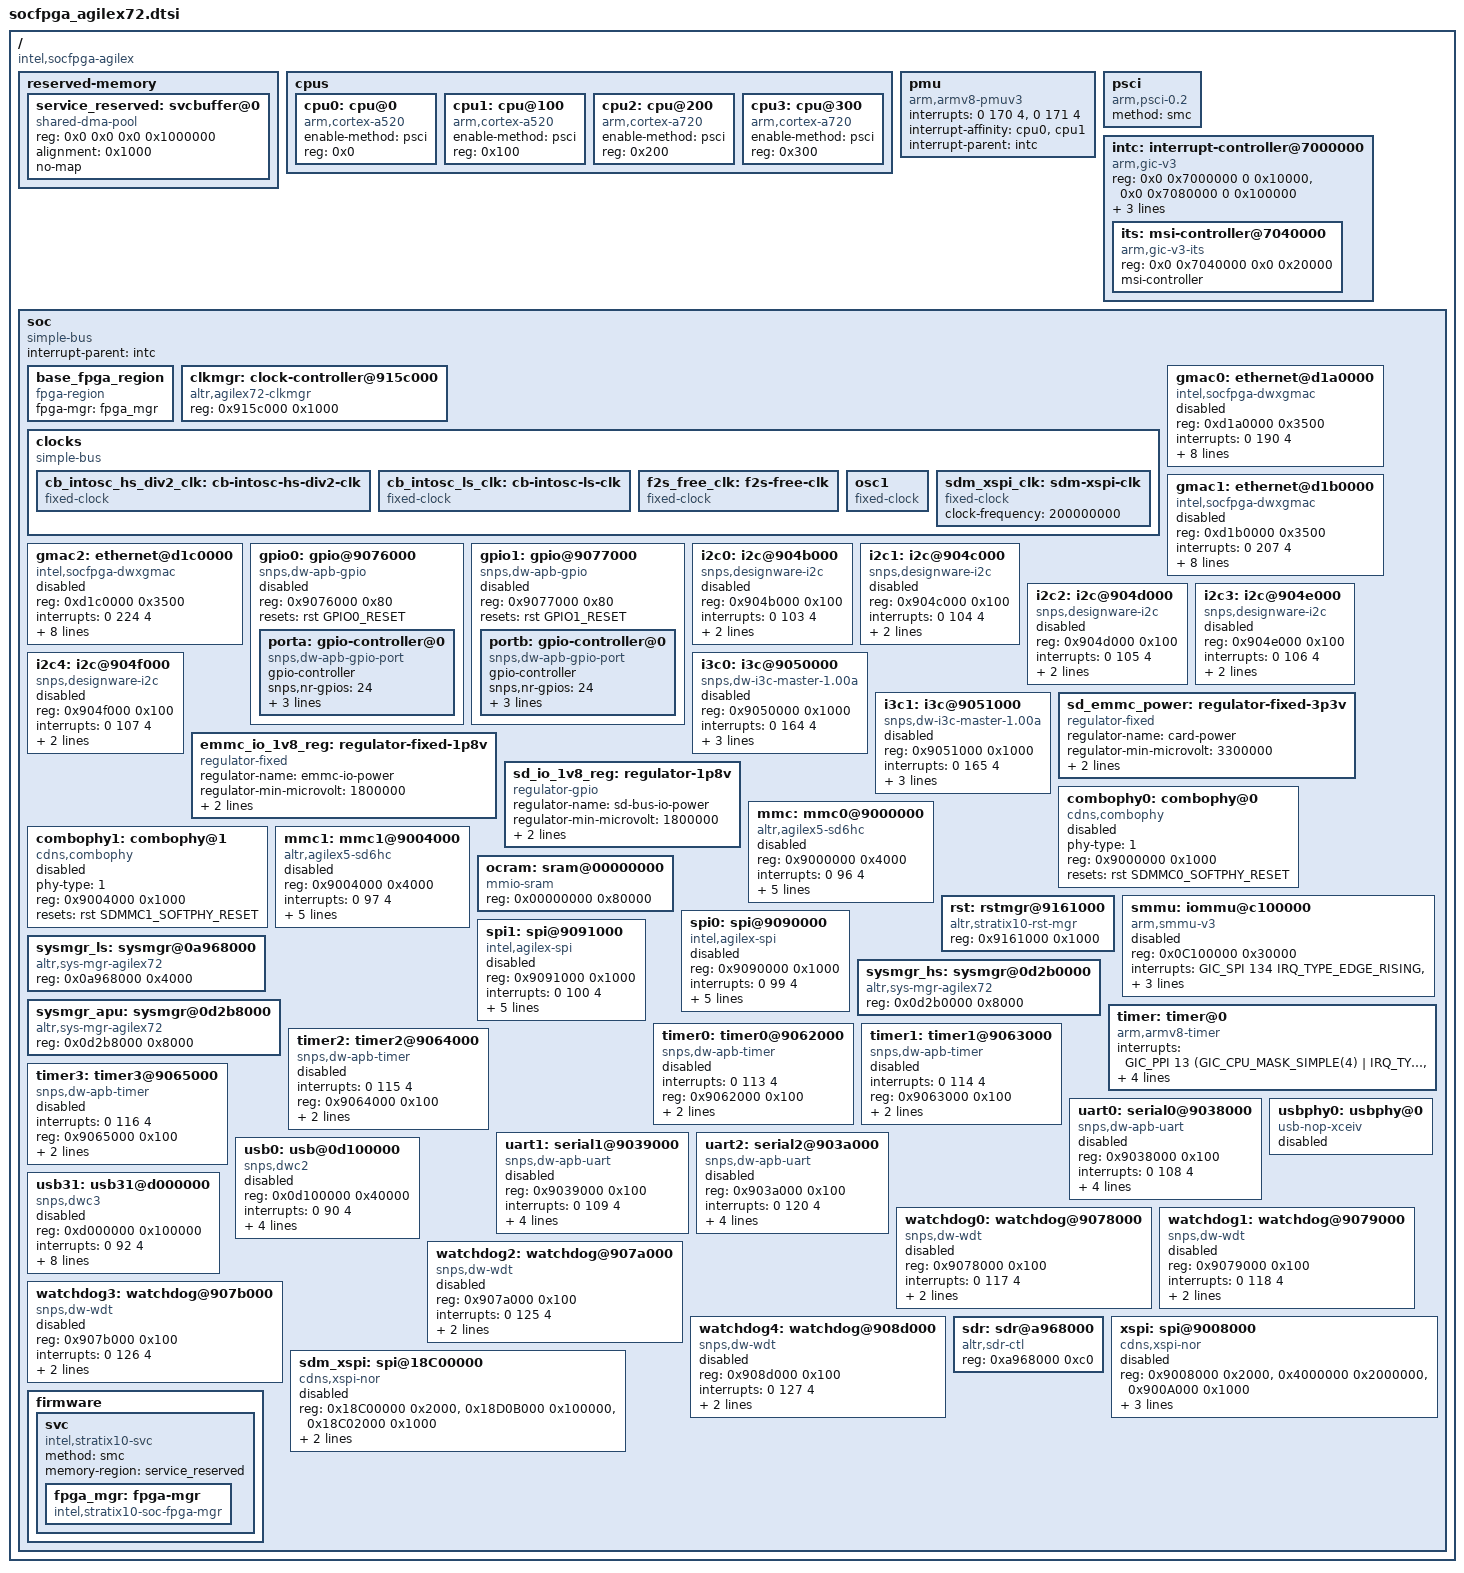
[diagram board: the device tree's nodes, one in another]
// SPDX-License-Identifier:     GPL-2.0
/*
 * Copyright (C) 2025-2026 Altera Corporation <www.altera.com>
 */

/dts-v1/;
#include <dt-bindings/reset/altr,rst-mgr-agilex72.h>
#include <dt-bindings/gpio/gpio.h>
#include <dt-bindings/clock/altr,agilex72-clkmgr.h>
#include <dt-bindings/interrupt-controller/arm-gic.h>
#include <dt-bindings/interrupt-controller/irq.h>

/ {
	compatible = "intel,socfpga-agilex";
	#address-cells = <2>;
	#size-cells = <2>;

	reserved-memory {
		#address-cells = <2>;
		#size-cells = <2>;
		ranges;

		service_reserved: svcbuffer@0 {
			compatible = "shared-dma-pool";
			reg = <0x0 0x0 0x0 0x1000000>;
			alignment = <0x1000>;
			no-map;
		};
	};

	cpus {
		#address-cells = <1>;
		#size-cells = <0>;

		cpu0: cpu@0 {
			compatible = "arm,cortex-a520";
			device_type = "cpu";
			enable-method = "psci";
			reg = <0x0>;
		};

		cpu1: cpu@100 {
			compatible = "arm,cortex-a520";
			device_type = "cpu";
			enable-method = "psci";
			reg = <0x100>;
		};

		cpu2: cpu@200 {
			compatible = "arm,cortex-a720";
			device_type = "cpu";
			enable-method = "psci";
			reg = <0x200>;
		};

		cpu3: cpu@300 {
			compatible = "arm,cortex-a720";
			device_type = "cpu";
			enable-method = "psci";
			reg = <0x300>;
		};
	};

	pmu {
		compatible = "arm,armv8-pmuv3";
		interrupts = <0 170 4>,
			     <0 171 4>;
		interrupt-affinity = <&cpu0>,
				     <&cpu1>;
		interrupt-parent = <&intc>;
	};

	psci {
		compatible = "arm,psci-0.2";
		method = "smc";
	};

	intc: interrupt-controller@7000000 {
		compatible = "arm,gic-v3";
		reg = <0x0 0x7000000 0 0x10000>,
			<0x0 0x7080000 0 0x100000>;
		ranges;
		#interrupt-cells = <3>;
		#address-cells = <2>;
		#size-cells = <2>;
		interrupt-controller;
		#redistributor-regions = <1>;
		redistributor-stride = <0x0 0x40000>;

		its: msi-controller@7040000 {
			compatible = "arm,gic-v3-its";
			reg = <0x0 0x7040000 0x0 0x20000>;
			msi-controller;
			#msi-cells = <1>;
		};
	};

	soc {
		#address-cells = <1>;
		#size-cells = <1>;
		compatible = "simple-bus";
		device_type = "soc";
		interrupt-parent = <&intc>;
		ranges = <0 0 0 0xffffffff>;

		base_fpga_region {
			#address-cells = <0x1>;
			#size-cells = <0x1>;
			compatible = "fpga-region";
			fpga-mgr = <&fpga_mgr>;
		};

		clkmgr: clock-controller@915c000 {
			compatible = "altr,agilex72-clkmgr";
			reg = <0x915c000 0x1000>;
			#clock-cells = <1>;
		};

		clocks {
			compatible = "simple-bus";

			cb_intosc_hs_div2_clk: cb-intosc-hs-div2-clk {
				#clock-cells = <0>;
				compatible = "fixed-clock";
			};

			cb_intosc_ls_clk: cb-intosc-ls-clk {
				#clock-cells = <0>;
				compatible = "fixed-clock";
			};

			f2s_free_clk: f2s-free-clk {
				#clock-cells = <0>;
				compatible = "fixed-clock";
			};

			osc1: osc1 {
				#clock-cells = <0>;
				compatible = "fixed-clock";
			};

			sdm_xspi_clk: sdm-xspi-clk {
				#clock-cells = <0>;
				compatible = "fixed-clock";
				clock-frequency = <200000000>;
			};
		};
		gmac0: ethernet@d1a0000 {
			compatible = "intel,socfpga-dwxgmac", "snps,dwxgmac-2.10", "snps,dwxgmac";
			reg = <0xd1a0000 0x3500>;
			interrupts = <0 190 4>;
			interrupt-names = "macirq";
			mac-address = [00 00 00 00 00 00];
			resets = <&rst EMAC0_RESET>;
			reset-names = "stmmaceth";
			tx-fifo-depth = <32768>;
			rx-fifo-depth = <16384>;
			iommus = <&smmu 1>;
			altr,sysmgr-syscon = <&sysmgr_hs 0x6C 0>;
			clocks = <&clkmgr AGILEX72_EMAC0_CLK>,
				 <&clkmgr AGILEX72_EMAC_PTP_CLK>;
			clock-names = "stmmaceth", "ptp_ref";
			status = "disabled";
		};

		gmac1: ethernet@d1b0000 {
			compatible = "intel,socfpga-dwxgmac", "snps,dwxgmac-2.10", "snps,dwxgmac";
			reg = <0xd1b0000 0x3500>;
			interrupts = <0 207 4>;
			interrupt-names = "macirq";
			mac-address = [00 00 00 00 00 00];
			resets = <&rst EMAC1_RESET>;
			reset-names = "stmmaceth";
			tx-fifo-depth = <32768>;
			rx-fifo-depth = <16384>;
			iommus = <&smmu 2>;
			altr,sysmgr-syscon = <&sysmgr_hs 0x74 0>;
			clocks = <&clkmgr AGILEX72_EMAC1_CLK>,
				 <&clkmgr AGILEX72_EMAC_PTP_CLK>;
			clock-names = "stmmaceth", "ptp_ref";
			status = "disabled";
		};

		gmac2: ethernet@d1c0000 {
			compatible = "intel,socfpga-dwxgmac", "snps,dwxgmac-2.10", "snps,dwxgmac";
			reg = <0xd1c0000 0x3500>;
			interrupts = <0 224 4>;
			interrupt-names = "macirq";
			mac-address = [00 00 00 00 00 00];
			resets = <&rst EMAC2_RESET>;
			reset-names = "stmmaceth";
			tx-fifo-depth = <32768>;
			rx-fifo-depth = <16384>;
			iommus = <&smmu 3>;
			altr,sysmgr-syscon = <&sysmgr_hs 0x7C 0>;
			clocks = <&clkmgr AGILEX72_EMAC2_CLK>,
				 <&clkmgr AGILEX72_EMAC_PTP_CLK>;
			clock-names = "stmmaceth", "ptp_ref";
			status = "disabled";
		};

		gpio0: gpio@9076000 {
			#address-cells = <1>;
			#size-cells = <0>;
			compatible = "snps,dw-apb-gpio";
			reg = <0x9076000 0x80>;
			resets = <&rst GPIO0_RESET>;
			status = "disabled";

			porta: gpio-controller@0 {
				compatible = "snps,dw-apb-gpio-port";
				gpio-controller;
				#gpio-cells = <2>;
				snps,nr-gpios = <24>;
				reg = <0>;
				interrupt-controller;
				#interrupt-cells = <2>;
				interrupts = <0 110 4>;
			};
		};

		gpio1: gpio@9077000 {
			#address-cells = <1>;
			#size-cells = <0>;
			compatible = "snps,dw-apb-gpio";
			reg = <0x9077000 0x80>;
			resets = <&rst GPIO1_RESET>;
			status = "disabled";

			portb: gpio-controller@0 {
				compatible = "snps,dw-apb-gpio-port";
				gpio-controller;
				#gpio-cells = <2>;
				snps,nr-gpios = <24>;
				reg = <0>;
				interrupt-controller;
				#interrupt-cells = <2>;
				interrupts = <0 111 4>;
			};
		};

		i2c0: i2c@904b000 {
			#address-cells = <1>;
			#size-cells = <0>;
			compatible = "snps,designware-i2c";
			reg = <0x904b000 0x100>;
			interrupts = <0 103 4>;
			resets = <&rst I2C_EMAC0_RESET>;
			clocks = <&clkmgr AGILEX72_LSP_SP_CLK>;
			status = "disabled";
		};

		i2c1: i2c@904c000 {
			#address-cells = <1>;
			#size-cells = <0>;
			compatible = "snps,designware-i2c";
			reg = <0x904c000 0x100>;
			interrupts = <0 104 4>;
			resets = <&rst I2C_EMAC1_RESET>;
			clocks = <&clkmgr AGILEX72_LSP_SP_CLK>;
			status = "disabled";
		};

		i2c2: i2c@904d000 {
			#address-cells = <1>;
			#size-cells = <0>;
			compatible = "snps,designware-i2c";
			reg = <0x904d000 0x100>;
			interrupts = <0 105 4>;
			resets = <&rst I2C_EMAC2_RESET>;
			clocks = <&clkmgr AGILEX72_LSP_SP_CLK>;
			status = "disabled";
		};

		i2c3: i2c@904e000 {
			#address-cells = <1>;
			#size-cells = <0>;
			compatible = "snps,designware-i2c";
			reg = <0x904e000 0x100>;
			interrupts = <0 106 4>;
			resets = <&rst I2C0_RESET>;
			clocks = <&clkmgr AGILEX72_LSP_SP_CLK>;
			status = "disabled";
		};

		i2c4: i2c@904f000 {
			#address-cells = <1>;
			#size-cells = <0>;
			compatible = "snps,designware-i2c";
			reg = <0x904f000 0x100>;
			interrupts = <0 107 4>;
			resets = <&rst I2C1_RESET>;
			clocks = <&clkmgr AGILEX72_LSP_SP_CLK>;
			status = "disabled";
		};

		i3c0: i3c@9050000 {
			compatible = "snps,dw-i3c-master-1.00a";
			reg = <0x9050000 0x1000>;
			#address-cells = <1>;
			#size-cells = <0>;
			interrupts = <0 164 4>;
			resets = <&rst I3C0_RESET>;
			max_devices = <11>;
			clocks = <&clkmgr AGILEX72_LSP_MP_CLK>;
			status = "disabled";
		};

		i3c1: i3c@9051000 {
			compatible = "snps,dw-i3c-master-1.00a";
			reg = <0x9051000 0x1000>;
			#address-cells = <1>;
			#size-cells = <0>;
			interrupts = <0 165 4>;
			resets = <&rst I3C1_RESET>;
			clocks = <&clkmgr AGILEX72_LSP_MP_CLK>;
			max_devices = <11>;
			status = "disabled";
		};

		sd_emmc_power: regulator-fixed-3p3v {
			compatible = "regulator-fixed";
			regulator-name = "card-power";
			regulator-min-microvolt = <3300000>;
			regulator-max-microvolt = <3300000>;
			regulator-always-on;
		};

		emmc_io_1v8_reg: regulator-fixed-1p8v {
			compatible = "regulator-fixed";
			regulator-name = "emmc-io-power";
			regulator-min-microvolt = <1800000>;
			regulator-max-microvolt = <1800000>;
			regulator-always-on;
		};

		sd_io_1v8_reg: regulator-1p8v {
			compatible = "regulator-gpio";
			regulator-name = "sd-bus-io-power";
			regulator-min-microvolt = <1800000>;
			regulator-max-microvolt = <3300000>;
			states =	<1800000 0x1>,
						<3300000 0x0>;
		};

		combophy0: combophy@0 {
			#phy-cells = <0>;
			phy-type = <1>;
			compatible = "cdns,combophy";
			reg = <0x9000000 0x1000>;
			resets = <&rst SDMMC0_SOFTPHY_RESET>;
			reset-names = "reset";
			status = "disabled";
		};

		mmc: mmc0@9000000 {
			#address-cells = <1>;
			#size-cells = <0>;
			compatible = "altr,agilex5-sd6hc", "cdns,sd6hc";
			reg = <0x9000000 0x4000>;
			interrupts = <0 96 4>;
			phys = <&combophy0>;
			phy-names = "combo-phy";
			clocks = <&clkmgr AGILEX72_LSP_MP_CLK>,
				 <&clkmgr AGILEX72_SDMMC0_SDMCLK>;
			clock-names = "biu", "ciu";
			fifo-depth = <0x800>;
			resets = <&rst SDMMC0_RESET>;
			reset-names = "reset";
			status = "disabled";
		};

		combophy1: combophy@1 {
			#phy-cells = <0>;
			phy-type = <1>;
			compatible = "cdns,combophy";
			reg = <0x9004000 0x1000>;
			resets = <&rst SDMMC1_SOFTPHY_RESET>;
			reset-names = "reset";
			status = "disabled";
		};

		mmc1: mmc1@9004000 {
			#address-cells = <1>;
			#size-cells = <0>;
			compatible = "altr,agilex5-sd6hc", "cdns,sd6hc";
			reg = <0x9004000 0x4000>;
			interrupts = <0 97 4>;
			phys = <&combophy1>;
			phy-names = "combo-phy";
			clocks = <&clkmgr AGILEX72_LSP_MP_CLK>,
				 <&clkmgr AGILEX72_SDMMC1_SDMCLK>;
			clock-names = "biu", "ciu";
			fifo-depth = <0x800>;
			resets = <&rst SDMMC1_RESET>;
			reset-names = "reset";
			status = "disabled";
		};

		ocram: sram@00000000 {
			compatible = "mmio-sram";
			reg = <0x00000000 0x80000>;
		};

		rst: rstmgr@9161000 {
			#reset-cells = <1>;
			compatible = "altr,stratix10-rst-mgr";
			reg = <0x9161000 0x1000>;
		};

		smmu: iommu@c100000 {
			compatible = "arm,smmu-v3";
			reg = <0x0C100000 0x30000>;
			interrupts = <GIC_SPI 134 IRQ_TYPE_EDGE_RISING>,
				     <GIC_SPI 129 IRQ_TYPE_EDGE_RISING>,
				     <GIC_SPI 132 IRQ_TYPE_EDGE_RISING>;
			interrupt-names = "eventq", "gerror", "priq";
			dma-coherent;
			#iommu-cells = <1>;
			status = "disabled";
		};

		spi0: spi@9090000 {
			compatible = "intel,agilex-spi",
				     "snps,dw-apb-ssi-4.00a", "snps,dw-apb-ssi";
			#address-cells = <1>;
			#size-cells = <0>;
			reg = <0x9090000 0x1000>;
			interrupts = <0 99 4>;
			resets = <&rst SPIM0_RESET>;
			reg-io-width = <4>;
			num-cs = <4>;
			clocks = <&clkmgr AGILEX72_LSP_MAIN_CLK>;
			spi-max-frequency = <50000000>;
			status = "disabled";
		};

		spi1: spi@9091000 {
			compatible = "intel,agilex-spi",
				     "snps,dw-apb-ssi-4.00a", "snps,dw-apb-ssi";
			#address-cells = <1>;
			#size-cells = <0>;
			reg = <0x9091000 0x1000>;
			interrupts = <0 100 4>;
			resets = <&rst SPIM1_RESET>;
			reg-io-width = <4>;
			num-cs = <4>;
			clocks = <&clkmgr AGILEX72_LSP_MAIN_CLK>;
			spi-max-frequency = <50000000>;
			status = "disabled";
		};

		/*
		 * AGILEX72 exposes the System Manager as three physically separate
		 * register windows (Low-Speed Core, High-Speed Core, and APU
		 * Core) rather than the single contiguous block used by other
		 * SoC64 family members. Each block is described as its own
		 * standalone syscon so that consumers reference the exact
		 * region they need via a regular 2-cell altr,sysmgr-syscon
		 * phandle. Cross-region access, when it ever becomes
		 * necessary, is achieved by holding more than one phandle.
		 */
		sysmgr_ls: sysmgr@0a968000 {
			compatible = "altr,sys-mgr-agilex72", "altr,sys-mgr";
			reg = <0x0a968000 0x4000>;
		};

		sysmgr_hs: sysmgr@0d2b0000 {
			compatible = "altr,sys-mgr-agilex72", "altr,sys-mgr";
			reg = <0x0d2b0000 0x8000>;
		};

		sysmgr_apu: sysmgr@0d2b8000 {
			compatible = "altr,sys-mgr-agilex72", "altr,sys-mgr";
			reg = <0x0d2b8000 0x8000>;
		};

		/* Local timer */
		timer: timer@0 {
			compatible = "arm,armv8-timer";
			interrupts = <GIC_PPI 13 (GIC_CPU_MASK_SIMPLE(4) | IRQ_TYPE_LEVEL_LOW)>,
				     <GIC_PPI 14 (GIC_CPU_MASK_SIMPLE(4) | IRQ_TYPE_LEVEL_LOW)>,
				     <GIC_PPI 11 (GIC_CPU_MASK_SIMPLE(4) | IRQ_TYPE_LEVEL_LOW)>,
				     <GIC_PPI 10 (GIC_CPU_MASK_SIMPLE(4) | IRQ_TYPE_LEVEL_LOW)>;
			status = "okay";
			always-on;
		};

		timer0: timer0@9062000 {
			compatible = "snps,dw-apb-timer";
			interrupts = <0 113 4>;
			reg = <0x9062000 0x100>;
			resets = <&rst SPTIMER0_RESET>;
			clocks = <&clkmgr AGILEX72_SPTIMER_0_PCLK>;
			clock-names = "timer";
			status = "disabled";
		};

		timer1: timer1@9063000 {
			compatible = "snps,dw-apb-timer";
			interrupts = <0 114 4>;
			reg = <0x9063000 0x100>;
			resets = <&rst SPTIMER1_RESET>;
			clocks = <&clkmgr AGILEX72_SPTIMER_1_PCLK>;
			clock-names = "timer";
			status = "disabled";
		};

		timer2: timer2@9064000 {
			compatible = "snps,dw-apb-timer";
			interrupts = <0 115 4>;
			reg = <0x9064000 0x100>;
			resets = <&rst L4SYSTIMER0_RESET>;
			clocks = <&clkmgr AGILEX72_LSP_SYS_FREE_CLK>;
			clock-names = "timer";
			status = "disabled";
		};

		timer3: timer3@9065000 {
			compatible = "snps,dw-apb-timer";
			interrupts = <0 116 4>;
			reg = <0x9065000 0x100>;
			resets = <&rst L4SYSTIMER1_RESET>;
			clocks = <&clkmgr AGILEX72_LSP_SYS_FREE_CLK>;
			clock-names = "timer";
			status = "disabled";
		};

		uart0: serial0@9038000 {
			compatible = "snps,dw-apb-uart";
			reg = <0x9038000 0x100>;
			interrupts = <0 108 4>;
			reg-shift = <2>;
			reg-io-width = <4>;
			resets = <&rst UART0_RESET>;
			status = "disabled";
			clocks = <&clkmgr AGILEX72_LSP_SP_CLK>;
		};

		uart1: serial1@9039000 {
			compatible = "snps,dw-apb-uart";
			reg = <0x9039000 0x100>;
			interrupts = <0 109 4>;
			reg-shift = <2>;
			reg-io-width = <4>;
			resets = <&rst UART1_RESET>;
			clocks = <&clkmgr AGILEX72_LSP_SP_CLK>;
			status = "disabled";
		};

		uart2: serial2@903a000 {
			compatible = "snps,dw-apb-uart";
			reg = <0x903a000 0x100>;
			interrupts = <0 120 4>;
			reg-shift = <2>;
			reg-io-width = <4>;
			resets = <&rst UART2_RESET>;
			status = "disabled";
			clocks = <&clkmgr AGILEX72_LSP_SP_CLK>;
		};

		usbphy0: usbphy@0 {
			#phy-cells = <0>;
			compatible = "usb-nop-xceiv";
			status = "disabled";
		};

		usb0: usb@0d100000 {
			compatible = "snps,dwc2";
			reg = <0x0d100000 0x40000>;
			interrupts = <0 90 4>;
			phys = <&usbphy0>;
			phy-names = "usb2-phy";
			resets = <&rst USB20TG_RESET>;
			reset-names = "dwc2";
			clocks = <&clkmgr AGILEX72_HSP_MP_CLK>;
			clock-names = "otg";
			iommus = <&smmu 6>;
			status = "disabled";
		};

		usb31: usb31@d000000 {
			compatible = "snps,dwc3";
			reg = <0xd000000 0x100000>;
			interrupts = <0 92 4>;
			resets = <&rst USB31_RESET>, <&rst USB31PHY_RESET>;
			reset-names = "dwc3", "dwc3-phy";
			phys = <&usbphy0>, <&usbphy0>;
			phy-names = "usb2-phy", "usb3-phy";
			dr_mode = "host";
			maximum-speed = "super-speed";
			snps,dis_u2_susphy_quirk;
			clocks = <&clkmgr AGILEX72_USB31_FREE_CLK>,
				 <&clkmgr AGILEX72_HSP_MAIN_CLK>,
				 <&clkmgr AGILEX72_USB31_SUSPEND_CLK>;
			clock-names = "ref", "bus_early", "suspend";
			status = "disabled";
		};

		watchdog0: watchdog@9078000 {
			compatible = "snps,dw-wdt";
			reg = <0x9078000 0x100>;
			interrupts = <0 117 4>;
			resets = <&rst WATCHDOG0_RESET>;
			clocks = <&clkmgr AGILEX72_LSP_SYS_FREE_CLK>;
			status = "disabled";
		};

		watchdog1: watchdog@9079000 {
			compatible = "snps,dw-wdt";
			reg = <0x9079000 0x100>;
			interrupts = <0 118 4>;
			resets = <&rst WATCHDOG1_RESET>;
			clocks = <&clkmgr AGILEX72_LSP_SYS_FREE_CLK>;
			status = "disabled";
		};

		watchdog2: watchdog@907a000 {
			compatible = "snps,dw-wdt";
			reg = <0x907a000 0x100>;
			interrupts = <0 125 4>;
			resets = <&rst WATCHDOG2_RESET>;
			clocks = <&clkmgr AGILEX72_LSP_SYS_FREE_CLK>;
			status = "disabled";
		};

		watchdog3: watchdog@907b000 {
			compatible = "snps,dw-wdt";
			reg = <0x907b000 0x100>;
			interrupts = <0 126 4>;
			resets = <&rst WATCHDOG3_RESET>;
			clocks = <&clkmgr AGILEX72_LSP_SYS_FREE_CLK>;
			status = "disabled";
		};

		watchdog4: watchdog@908d000 {
			compatible = "snps,dw-wdt";
			reg = <0x908d000 0x100>;
			interrupts = <0 127 4>;
			resets = <&rst WATCHDOG4_RESET>;
			clocks = <&clkmgr AGILEX72_LSP_SYS_FREE_CLK>;
			status = "disabled";
		};

		sdr: sdr@a968000 {
			compatible = "altr,sdr-ctl", "syscon";
			reg = <0xa968000 0xc0>;
		};

		xspi: spi@9008000 {
			compatible = "cdns,xspi-nor";
			#address-cells = <1>;
			#size-cells = <0>;
			reg = <0x9008000 0x2000>,
			      <0x4000000 0x2000000>,
			      <0x900A000 0x1000>;
			reg-names = "io", "sdma", "aux";
			interrupts = <0 260 4>;
			clocks = <&clkmgr AGILEX72_LSP_MP_CLK>,
				 <&clkmgr AGILEX72_XSPI_CLK>;
			clock-names = "reg-clk", "core-clk";
			status = "disabled";
		};

		sdm_xspi: spi@18C00000 {
			compatible = "cdns,xspi-nor";
			#address-cells = <1>;
			#size-cells = <0>;
			reg = <0x18C00000 0x2000>,
			      <0x18D0B000 0x100000>,
			      <0x18C02000 0x1000>;
			reg-names = "io", "sdma", "aux";
			interrupts = <0 3 4>;
			clocks = <&sdm_xspi_clk>;
			status = "disabled";
		};

		firmware {
			svc {
				compatible = "intel,stratix10-svc";
				method = "smc";
				memory-region = <&service_reserved>;

				fpga_mgr: fpga-mgr {
					compatible = "intel,stratix10-soc-fpga-mgr";
				};
			};
		};
	};

};
